# MMCSD2_CTL_CFG register map
Vendor: Texas Instruments
Peripheral module from a debugger description file (folder J7ES).
Registers are 16-bit, read-only, reset 0x0 unless marked. A register's access mark holds for its fields unless they carry their own. Offsets are as the file gives them; lines under a group give offsets from that group; [hi:lo] are bit positions; {n}, {i} and the like mark numbered series; 'fields as' and 'values as' point back to an identical list; <NAME> marks a mode.

## MMCSD2_CTL_CFG (part 1 of 3)
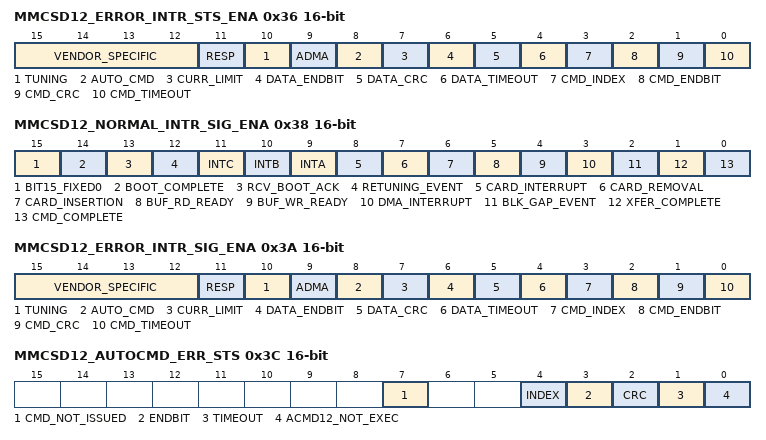
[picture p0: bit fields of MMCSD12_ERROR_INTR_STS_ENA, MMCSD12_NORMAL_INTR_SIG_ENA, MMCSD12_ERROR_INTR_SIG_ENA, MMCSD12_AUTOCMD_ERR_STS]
0x36 MMCSD12_ERROR_INTR_STS_ENA rw — This register is used to enable the register fields.
  [15:12] VENDOR_SPECIFIC — Vendor Specific Error Status Enable N/A
  [11] RESP — Response Error Status Enable (SD Mode Only) 0h: Masked 1h: Enabled
  [10] TUNING — Tuning Error Status Enable (UHS-I Only) 0h: Masked 1h: Enabled
  [9] ADMA — ADMA Error Status Enable 0h: Masked 1h: Enabled
  [8] AUTO_CMD — Auto CMD Error Status Enable (SD Mode Only) 0h: Masked 1h: Enabled
  [7] CURR_LIMIT — Current Limit Error Status Enable 0h: Masked 1h: Enabled
  [6] DATA_ENDBIT — Data End Bit Error Status Enable (SD Mode Only) 0h: Masked 1h: Enabled
  [5] DATA_CRC — Data CRC Error Status Enable (SD Mode Only) 0h: Masked 1h: Enabled
  [4] DATA_TIMEOUT — Data Timeout Error Status Enable (SD Mode Only) 0h: Masked 1h: Enabled
  [3] CMD_INDEX — Command Index Error Status Enable (SD Mode Only) 0h: Masked 1h: Enabled
  [2] CMD_ENDBIT — Command End Bit Error Status Enable (SD Mode Only) 0h: Masked 1h: Enabled
  [1] CMD_CRC — Command CRC Error Status Enable (SD Mode Only) 0h: Masked 1h: Enabled
  [0] CMD_TIMEOUT — Command Timeout Error Status Enable (SD Mode Only) 0h: Masked 1h: Enabled
0x38 MMCSD12_NORMAL_INTR_SIG_ENA access per field — Normal Interrupt Signal Enable Register This register is used to select which interrupt status is indicated to the Host System as the Interrupt. These status bits all share the sample 1 bit interrupt line. Setting any of these bits to 1h enables Interrupt generation.
  [15] BIT15_FIXED0 ro — Fixed to 0 The HD shall control error Interrupts using the
  [14] BOOT_COMPLETE rw — Boot Terminate Interrupt Signal Enable 0h: Masked 1h: Enabled
  [13] RCV_BOOT_ACK rw — Boot Acknowledge Receive Signal Enable 0h: Masked 1h: Enabled
  [12] RETUNING_EVENT rw — Re-Tuning Event Signal Enable (UHS-I Only) 0h: Masked 1h: Enabled
  [11] INTC rw — INT_C Signal Enable (Embedded) 0h: Masked 1h: Enabled
  [10] INTB rw — INT_B Signal Enable (Embedded) 0h: Masked 1h: Enabled
  [9] INTA rw — INT_A Signal Enable (Embedded) 0h: Masked 1h: Enabled
  [8] CARD_INTERRUPT rw — Card Interrupt Signal Enable 0h: Masked 1h: Enabled
  [7] CARD_REMOVAL rw — Card Removal Signal Enable 0h: Masked 1h: Enabled
  [6] CARD_INSERTION rw — Card Insertion Signal Enable 0h: Masked 1h: Enabled
  [5] BUF_RD_READY rw — Buffer Read Ready Signal Enable 0h: Masked 1h: Enabled
  [4] BUF_WR_READY rw — Buffer Write Ready Signal Enable 0h: Masked 1h: Enabled
  [3] DMA_INTERRUPT rw — DMA Interrupt Signal Enable 0h: Masked 1h: Enabled
  [2] BLK_GAP_EVENT rw — Block Gap Event Signal Enable 0h: Masked 1h: Enabled
  [1] XFER_COMPLETE rw — Transfer Complete Signal Enable 0h: Masked 1h: Enabled
  [0] CMD_COMPLETE rw — Command Complete Signal Enable 0h: Masked 1h: Enabled
0x3A MMCSD12_ERROR_INTR_SIG_ENA rw — Error Interrupt Signal Enable Register This register is used to select which interrupt status is notified to the Host System as the Interrupt. These status bits all share the same 1 bit interrupt line. Setting any of these bits to 1h enables Interrupt generation.
  [15:12] VENDOR_SPECIFIC — Vendor Specific Error Signal Enable N/A
  [11] RESP — Response Error Signal Enable (SD Mode Only) 0h: Masked 1h: Enabled
  [10] TUNING — Tuning Error Signal Enable (UHS-I Only) 0h: Masked 1h: Enabled
  [9] ADMA — ADMA Error Signal Enable 0h: Masked 1h: Enabled
  [8] AUTO_CMD — Auto CMD Error Signal Enable (SD Mode Only) 0h: Masked 1h: Enabled
  [7] CURR_LIMIT — Current Limit Error Signal Enable 0h: Masked 1h: Enabled
  [6] DATA_ENDBIT — Data End Bit Error Signal Enable (SD Mode Only) 0h: Masked 1h: Enabled
  [5] DATA_CRC — Data CRC Error Signal Enable (SD Mode Only) 0h: Masked 1h: Enabled
  [4] DATA_TIMEOUT — Data Timeout Error Signal Enable (SD Mode Only) 0h: Masked 1h: Enabled
  [3] CMD_INDEX — Command Index Error Signal Enable (SD Mode Only) 0h: Masked 1h: Enabled
  [2] CMD_ENDBIT — Command End Bit Error Signal Enable (SD Mode Only) 0h: Masked 1h: Enabled
  [1] CMD_CRC — Command CRC Error Signal Enable (SD Mode Only) 0h: Masked 1h: Enabled
  [0] CMD_TIMEOUT — Command Timeout Error Signal Enable (SD Mode Only) 0h: Masked 1h: Enabled
0x3C MMCSD12_AUTOCMD_ERR_STS — This register is used to indicate CMD12 response error of Auto CMD12 and CMD23 response error of Auto CMD23. The Host driver can determine what kind of Auto CMD12/CMD23 errors occur by this register. Auto CMD23 errors are indicated in bit 04-01. This register is valid only when the Auto CMD Error is set.
  [7] CMD_NOT_ISSUED — Command Not Issued By Auto CMD12 Error Setting this bit to 1h means CMD_wo_DAT is not executed due to an Auto CMD12 error (D04- D01) in this register. This bit is set to 0h when Auto CMD Error is generated by Auto CMD23. 0h: No Error 1h: Not Issued
  [4] INDEX — Auto CMD Index Error Occurs if the Command Index error occurs in response to a command. 0h: No Error 1h: Error
  [3] ENDBIT — Auto CMD End Bit Error Occurs when detecting that the end bit of command response is 0h. 0h: No Error 1h: End Bit Error Generated
  [2] CRC — Auto CMD CRC Error Occurs when detecting a CRC error in the command response. 0h: No Error 1h: CRC Error Generated
  [1] TIMEOUT — Auto CMD Timeout Error Occurs if the no response is returned within 64 SDCLK cycles from the end bit of the command. If this bit is set to 1h, the other error status bits (D04 - D02) are meaningless. 0h: No Error 1h: Timeout
  [0] ACMD12_NOT_EXEC — Auto CMD12 not Executed If memory multiple block data transfer is not started due to command error, this bit is not set because it is not necessary to issue Auto CMD12. Setting this bit to 1h means the HC cannot issue Auto CMD12 to stop memory multiple block transfer due to some error. If this bit is set to 1h, other error status bits (D04 - D01) are meaningless. This bit is set to 0h when Auto CMD Error is generated by Auto CMD23. 0h: Executed 1h: Not Executed
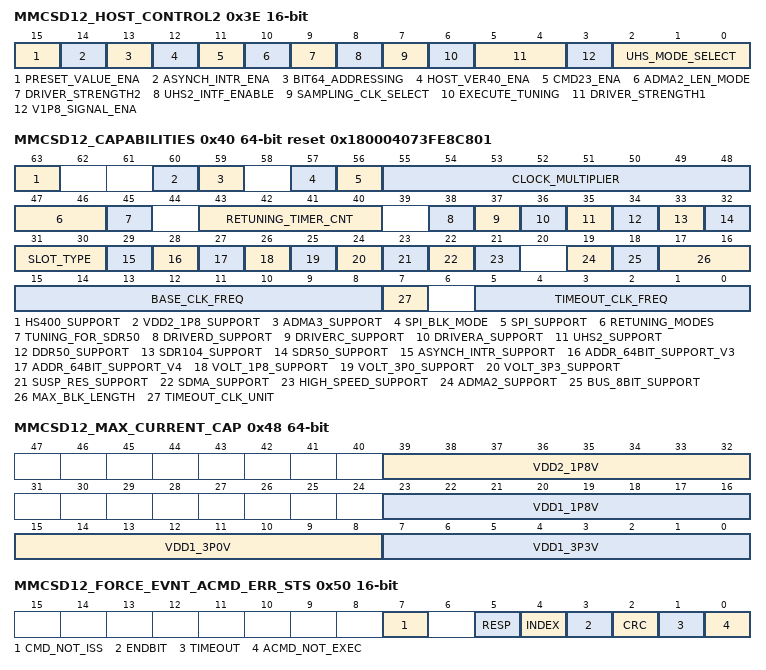
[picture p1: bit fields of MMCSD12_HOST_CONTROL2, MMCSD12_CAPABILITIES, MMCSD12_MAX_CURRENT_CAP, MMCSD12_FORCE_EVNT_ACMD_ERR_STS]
0x3E MMCSD12_HOST_CONTROL2 rw — This register is used to program UHS Mode Select, Driver Strength Select, Execute Tuning, Sampling Clock Select, Asynchronous Interrupt Enable and Preset Value Enable.
  [15] PRESET_VALUE_ENA — Preset Value Enable Host Controller Version 3.00 supports this bit. As the operating SDCLK frequency and I/O driver strength depend on the Host System implementation, it is difficult to determine these parameters in the Standard Host Driver. When the If this bit is set to 0h, SDCLK Frequency Select, Clock Generator Select in the If this bit is set to 1h, SDCLK Frequency Select, Clock Generator Select in the 0h: SDCLK and Driver Strength are controlled by Host Driver 1h: Automatic Selection by Preset Value are Enabled
  [14] ASYNCH_INTR_ENA — Asynchronous Interrupt Enable This bit can be set to 1h if a card support asynchronous interrupt and the 0h: Disabled 1h: Enabled
  [13] BIT64_ADDRESSING — 64-bit Addressing This field is effective when the Host Controller selects either of 32-bit or 64-bit addressing modes to access system memory. Whether 32-bit or 64-bit is determined by OS installed in a host system. Host Driver sets this bit depends on addressing mode of installed OS. Refer to 64-bit System Address Support in the 0h: 32-bits Addressing 1h: 64-bits Addressing
  [12] HOST_VER40_ENA — Host Version 4 Enable This bit selects either Version 3.00 compatible mode or Version 4.00 mode. In Version 4.00, support of 64-bit System Addressing is modified. All DMAs support 64-bit System Addressing. UHS-II supported Host Driver shall enable this bit. In Version 4.10, supported 32-bit Block Count for all operations. Functions of following fields are modified. SDMA uses the ADMA3 is selected by 128-bit descriptor is used instead of 96-bit descriptor when 64-bit Addressing is set to 1h. Either 32-bit or 64-bit system addressing is selected by 64-bit Addressing bit in this register instead of SDMA System Address register ( 0h: Version 3.00 Compatible Mode 1h: Version 4.Mode
  [11] CMD23_ENA — CMD23 Enable In memory card initialization, Host Driver Version 4.10 checks whether card supports CMD23 by checking a bit SCR[33]. If the card supports CMD23 (SCR[33] = 1h), this bit is set to 1h. This bit is used to select Auto CMD23 or Auto CMD12 for ADMA3 datatransfer. Refer to
  [10] ADMA2_LEN_MODE — ADMA2 Length Mode This bit selects one of ADMA2 Length Modes either 16-bit or 26-bit. 0h: 16-bit Data Length Mode 1h: 26-bit Data Length Mode
  [9] DRIVER_STRENGTH2 — Driver Strength Select This is the programmed Drive Strength output and Bit[2] of the sdhccore_drivestrength value.
  [8] UHS2_INTF_ENABLE — UHS-II Interface Enable This bit is used to enable UHS-II Interface. Before trying to start UHS-II initialization, this bit shall be set to 1h. Before trying to start SD mode initialization, this bit shall be set to 0h. This bit is used to enable UHS-II IF Detection, Lane Synchronization and In Dormant State in the Host Controller shall not leave unused SD 4-bit Interface lines (CLK, CMD and DAT[3:2]) floating in UHS-II mode by using pull-up or driving to low. When DAT[2] is used as interrupt input in UHS-II mode, DAT[2] of Host Controller is set to input and then DAT[2] of SDIO card is set to output to avoid conflict. 0h: 4-bit SD Interface Enabled 1h: UHS-II Interface Enabled
  [7] SAMPLING_CLK_SELECT — Sampling Clock Select (UHS-I Only) This bit is set by tuning procedure when the 0h: Fixed clock is used to sample data 1h: Tuned clock is used to sample data
  [6] EXECUTE_TUNING — Execute Tuning (UHS-I Only) This bit is set to 1h to start tuning procedure and automatically cleared when tuning procedure is completed. The result of tuning is indicated to the 0h: Not Tuned or Tuning Completed 1h: Execute Tuning
  [5:4] DRIVER_STRENGTH1 — Driver Strength Select (UHS-I Only) Host Controller output driver in 1.8 V signaling is selected by this bit. In 3.3 V signaling, this field is not effective. This field can be set depends on Driver Type A, C and D support bits in the If If 0h: Driver Type B is Selected (Default) 1h: Driver Type A is Selected 2h: Driver Type C is Selected 3h: Driver Type D is Selected
  [3] V1P8_SIGNAL_ENA — 1.8 V Signaling Enable (UHS-I Only) This bit controls voltage regulator for I/O cell. 3.3 V is supplied to the card regardless of signaling voltage. Setting this bit from 0h to 1h starts changing signal voltage from 3.3 V to 1.8 V. 1.8 V regulator output shall be stable within 5 ms. Host Controller clears this bit if switching to 1.8 V signaling fails. Clearing this bit from 1h to 0h starts changing signal voltage from 1.8 V to 3.3 V. 3.3 V regulator output shall be stable within 5 ms. Host Driver can set this bit to 1h when Host Controller supports 1.8 V signaling (one of support bits is set to 1h: SDR50, SDR104 or DDR50 in the 0h: 3.3 V Signaling 1h: 1.8 V Signaling
  [2:0] UHS_MODE_SELECT — UHS Mode Select (UHS-I Only) This field is used to select one of UHS-I modes or UHS-II mode. In case of UHS-I mode, this field is effective when the If the 0h: SDR12 1h: SDR25 2h: SDR50 3h: SDR104 4h: DDR50 5h: HS400 6h: Reserved 7h: UHS-II When SDR50, SDR104 or DDR50 is selected for SDIO card, interrupt detection at the block gap shall not be used. Read Wait timing is changed for these modes. Refer to the SDIO Specification Version 3.00 for more details.
0x40 MMCSD12_CAPABILITIES 64-bit reset 0x180004073FE8C801 — This register provides the HD with information specific to the HC implementation. The HC may implement these values as fixed or loaded from flash memory during power on initialization.
  [63] HS400_SUPPORT — HS400 Support 0h: HS400 is Not Supported 1h: HS400 is Supported
  [60] VDD2_1P8_SUPPORT — 1.8 V VDD2 Support This bit indicates that support of VDD2 on Host system. 0h: 1.8 V VDD2 is not supported 1h: 1.8 V VDD2 is supported
  [59] ADMA3_SUPPORT — ADMA3 Support This bit indicates that support of ADMA3 on Host Controller. 0h: ADMA3 is not supported 1h: ADMA3 is supported
  [57] SPI_BLK_MODE — SPI Block Mode This bit indicates whether SPI Block Mode is supported or not. 0h: Not Supported 1h: Supported
  [56] SPI_SUPPORT — SPI Mode This bit indicates whether SPI Mode is supported or not. 0h: Not Supported 1h: Supported
  [55:48] CLOCK_MULTIPLIER — Clock Multiplier This field indicates clock multiplier value of programmable clock generator. Refer to the FFh: Clock Multiplier M = 256 ---- 02h: Clock Multiplier M = 3 01h: Clock Multiplier M = 2 00h: Clock Multiplier is Not Supported
  [47:46] RETUNING_MODES — Re-tuning Modes (UHS-I Only) This field defines the re-tuning capability of a Host Controller and how to manage the data transfer length and a Re-Tuning Timer by the Host Driver. 0h: Mode 1 1h: Mode 2 2h: Mode 3 3h: Reserved There are two re-tuning timings: Re-Tuning Request and expiration of a Re-Tuning Timer. By receiving either timing, the Host Driver executes the re-tuning procedure just before a next command issue.
  [45] TUNING_FOR_SDR50 — Use Tuning for SDR50 (UHS-I Only) If this bit is set to 1h, this Host Controller requires tuning to operate SDR50 (tuning is always required to operate SDR104). 0h: SDR50 does not require tuning 1h: SDR50 requires tuning
  [43:40] RETUNING_TIMER_CNT — Timer Count for Re-Tuning (UHS-I Only) This field indicates an initial value of the Re-Tuning Timer for Re-Tuning Mode 1 to 3. 0h - Get information via other source 1h = 1 seconds 2h = 2 seconds 3h = 4 seconds 4h = 8 seconds ---- n = 2 ---- Bh = 1024 seconds Fh - Ch = Reserved
  [38] DRIVERD_SUPPORT — Driver Type D Support (UHS-I Only) This bit indicates support of Driver Type D for 1.8 Signaling. 0h: Driver Type D is Not Supported 1h: Driver Type D is Supported
  [37] DRIVERC_SUPPORT — Driver Type C Support (UHS-I Only) This bit indicates support of Driver Type C for 1.8 Signaling. 0h: Driver Type C is Not Supported 1h: Driver Type C is Supported
  [36] DRIVERA_SUPPORT — Driver Type A Support (UHS-I Only) This bit indicates support of Driver Type A for 1.8 Signaling. 0h: Driver Type A is Not Supported 1h: Driver Type A is Supported
  [35] UHS2_SUPPORT — UHS-II Support (UHS-II Only) This bit indicates whether Host Controller supports UHS-II. If this bit is set to 1h, the 0h: UHS-II is Not Supported 1h: UHS-II is Supported
  [34] DDR50_SUPPORT — DDR50 Support (UHS-I Only) This bit indicates whether DDR50 is supported or not. 0h: DDR50 is Not Supported 1h: DDR50 is Supported
  [33] SDR104_SUPPORT — SDR104 Support (UHS-I Only) This bit indicates whether SDR104 is supported or not. SDR104 requires tuning. 0h: SDR104 is Not Supported 1h: SDR104 is Supported
  [32] SDR50_SUPPORT — SDR50 Support (UHS-I Only) If SDR104 is supported, this bit shall be set to 1h. Bit 40 indicates whether SDR50 requires tuning or not. 0h: SDR50 is Not Supported 1h: SDR50 is Supported
  [31:30] SLOT_TYPE — Slot Type This field indicates usage of a slot by a specific Host System (a host controller register set is defined per slot). Embedded slot for one device (1h) means that only one non-removable device is connected to a SD bus slot. Shared Bus Slot (2h) can be set if Host Controller supports Shared Bus Control register. The Standard Host Driver controls only a removable card or one embedded device is connected to a SD bus slot. If a slot is configured for shared bus (2h), the Standard Host Driver does not control embedded devices connected to a shared bus. Shared bus slot is controlled by a specific host driver developed by a Host System. 0h: Removable Card Slot 1h: Embedded Slot for One Device 2h: Shared Bus Slot (SD Mode) 3h: UHS-II Multiple Embedded Devices
  [29] ASYNCH_INTR_SUPPORT — Asynchronous Interrupt Support (SD Mode Only) Refer to SDIO Specification Version 3.00 about asynchronous interrupt. 0h: Asynchronous Interrupt Not Supported 1h: Asynchronous Interrupt Supported
  [28] ADDR_64BIT_SUPPORT_V3 — 64-bit System Address Support for V3 Meaning of this bit is different depends on Versions. Host Controller Version 3.00 and Version 4.10 use this bit as 64-bit System Address support for V3 mode. Host Controller Version 4.00 uses this bit as 64-bit System Address support for both V3 and V4 modes. SDMA cannot be used in 64-bit Addressing in Version 3 mode. If this bit is set to 1h, 64-bit ADMA2 with using 96-bit Descriptor may be enabled as follows: In case of Host Controller Version 3, 64-bit ADMA2 is enabled by 0h: 64-bit System Address for V3 is not Supported 1h: 64-bit System Address for V3 is Supported
  [27] ADDR_64BIT_SUPPORT_V4 — 64-bit System Address Support for V4 This bit is added from Version 4.10. Setting 1h to this bit indicates that the Host Controller supports 64-bit System Addressing of Version 4 mode. When this bit is set to 1h, full or a part of 64-bit address should be used to decode Host Controller Registers so that Host Controller Registers can be placed above system memory area. 64-bit address decode of Host Controller Registers is effective regardless of setting to the If this bit is set to 1h, 64-bit DMA Addressing for Version 4 is enabled by setting 0h: 64-bit System Address for V4 is not Supported 1h: 64-bit System Address for V4 is Supported
  [26] VOLT_1P8_SUPPORT — Voltage Support 1.8 V This bit indicates whether the HC supports 1.8 V. 0h: 1.8 V Not Supported 1h: 1.8 V Supported
  [25] VOLT_3P0_SUPPORT — Voltage Support 3.0 V This bit indicates whether the HC supports 3.0 V. 0h: 3.0 V Not Supported 1h: 3.0 V Supported
  [24] VOLT_3P3_SUPPORT — Voltage Support 3.3 V This bit indicates whether the HC supports 3.3 V. 0h: 3.3 V Not Supported 1h: 3.3 V Supported
  [23] SUSP_RES_SUPPORT — Suspend/Resume Support This bit indicates whether the HC supports Suspend/Resume functionality. If this bit is 0h, the Suspend and Resume mechanism are not supported and the HD shall not issue either Suspend/Resume commands. 0h: Not Supported 1h: Supported
  [22] SDMA_SUPPORT — SDMA Support This bit indicates whether the HC is capable of using DMA to transfer data between system memory and the HC directly. Version 4.10 Host Controller shall support SDMA if ADMA2 is supported. 0h: SDMA Not Supported 1h: SDMA Supported
  [21] HIGH_SPEED_SUPPORT — High Speed Support This bit indicates whether the HC and the Host System support High Speed mode and they can supply SD Clock frequency from 25 MHz to 50 MHz (for SD)/20 MHz to 52 MHz (for MMC). 0h: High Speed Not Supported 1h: High Speed Supported
  [19] ADMA2_SUPPORT — ADMA2 Support 0h: ADMA2 Not support 1h: ADMA2 support
  [18] BUS_8BIT_SUPPORT — 8-bit Support for Embedded Device (Embedded) This bit indicates whether the Host Controller is capable of using 8-bit bus width mode. This bit is not effective when the 0h: 8-bit Bus Width Not Supported 1h: 8-bit Bus Width Supported
  [17:16] MAX_BLK_LENGTH — Max Block Length This value indicates the maximum block size that the HD can read and write to the buffer in the HC. The buffer shall transfer this block size without wait cycles. Three sizes can be defined as indicated below. 0h: 512 byte 1h: 1024 byte 2h: 2048 byte 3h: 4096 byte
  [15:8] BASE_CLK_FREQ — Base Clock Frequency for SD Clock (1) 6-bit Base Clock Frequency: This mode is supported by the Host Controller Version 1.00 and 2.00. Upper 2-bit is not effective and always 0. Unit values are 1 MHz. The supported clock range is 10 MHz to 63 MHz. 11xx xxxxb: Not Supported 0011 1111b: 63 MHz 0000 0010b: 2 MHz 0000 0001b: 1 MHz 0000 0000b: Get Information via another method (2) 8-bit Base Clock Frequency: This mode is supported by the Host Controller Version 3.00. Unit values are 1 MHz. The supported clock range is 10 MHz to 255 MHz. FFh: 255 MHz 02h: 2 MHz 01h: 1 MHz 00h: Get Information via another method If the real frequency is 16.5 MHz, the lager value shall be set 0001 0001b (17 MHz) because the Host Driver use this value to calculate the clock divider value (refer to the
  [7] TIMEOUT_CLK_UNIT — Timeout Clock Unit This bit shows the unit of base clock frequency used to detect Data Timeout Error ( 0h: KHz 1h: MHz
  [5:0] TIMEOUT_CLK_FREQ — Timeout Clock Frequency This bit shows the base clock frequency used to detect Data Timeout Error ( 0h: Get Information via another method Not 0h: 1 KHz to 63 KHz/1 MHz to 63 MHz
0x48 MMCSD12_MAX_CURRENT_CAP 64-bit — This register indicates maximum current capability for each voltage.
  [39:32] VDD2_1P8V — Maximum Current for 1.8 V VDD2
  [23:16] VDD1_1P8V — Maximum Current for 1.8 V VDD1
  [15:8] VDD1_3P0V — Maximum Current for 3.0 V VDD1
  [7:0] VDD1_3P3V — Maximum Current for 3.3 V VDD1
0x50 MMCSD12_FORCE_EVNT_ACMD_ERR_STS access per field — This register is not physically implemented, rather it is an address where the register can be written. Writing 1h: set each bit of the register Writing 0h: no effect By setting a bit in this register, the correspondent bit is set in the
  [7] CMD_NOT_ISS wo — Force Event for Command Not Issued by AUTO CMD12 Error 0h: Not Affected 1h: Command Not Issued By Auto CMD12 Error Status is set
  [5] RESP wo — Force Event for AUTO CMD Response Error 0h: Not Affected 1h: Auto CMD Response Error Status is set
  [4] INDEX wo — Force Event for AUTO CMD Index Error 0h: Not Affected 1h: Auto CMD Index Error Status is set
  [3] ENDBIT wo — Force Event for AUTO CMD End Bit Error 0h: Not Affected 1h: Auto CMD End bit Error Status is set
  [2] CRC wo — Force Event for AUTO CMD Timeout Error 0h: Not Affected 1h: Auto CMD CRC Error Status is set
  [1] TIMEOUT wo — Force Event for AUTO CMD Timeout Error 0h: Not Affected 1h: Auto CMD Timeout Error Status is set
  [0] ACMD_NOT_EXEC wo — Force Event for AUTO CMD12 Not Executed 0h: Not Affected 1h: Auto CMD12 Not Executed Status is set
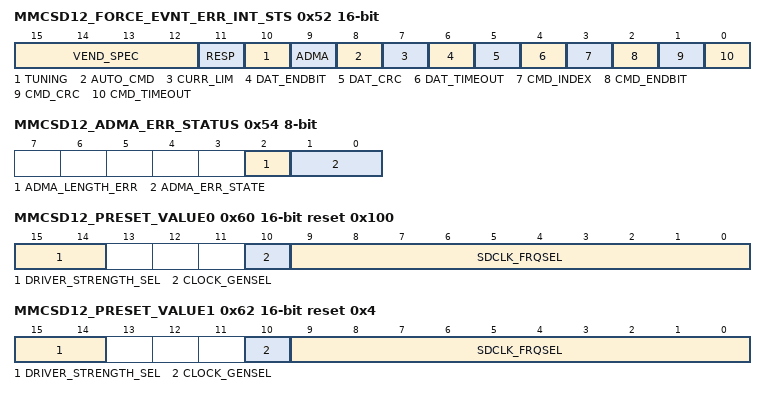
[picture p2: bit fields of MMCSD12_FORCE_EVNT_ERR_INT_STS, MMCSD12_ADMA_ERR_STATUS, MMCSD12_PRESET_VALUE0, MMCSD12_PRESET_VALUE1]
0x52 MMCSD12_FORCE_EVNT_ERR_INT_STS wo — This register is not physically implemented, rather it is an address where the register can be written. The register is not a physically implemented register. Rather, it is an address at which the register can be written. The effect of a write to this address will be reflected in the register if the corresponding bit of the register is set. Writing 1h: set each bit of the register Writing 0h: no effect
  [15:12] VEND_SPEC
  [11] RESP — Force Event for Response Error 0h: Not Affected 1h: Response Error Status is set
  [10] TUNING — Force Event for Tuning Error 0h: Not Affected 1h: Tuning Error Status is set
  [9] ADMA — Force Event for ADMA Error 0h: Not Affected 1h: ADMA Error Status is set
  [8] AUTO_CMD — Force Event for Auto CMD Error 0h: Not Affected 1h: Auto CMD Error Status is set
  [7] CURR_LIM — Force Event for Current Limit Error 0h: Not Affected 1h: Current Limit Error Status is set
  [6] DAT_ENDBIT — Force Event for Data End Bit Error 0h: Not Affected 1h: Data End Bit Error Status is set
  [5] DAT_CRC — Force Event for Data CRC Error 0h: Not Affected 1h: CRC Error Status is set
  [4] DAT_TIMEOUT — Force Event for Data Timeout Error 0h: Not Affected 1h: Timeout Error Status is set
  [3] CMD_INDEX — Force Event for Command Index Error 0h: Not Affected 1h: Command Index Error Status is set
  [2] CMD_ENDBIT — Force Event for Command End Bit Error 0h: Not Affected 1h: Command End Bit Error Status is set
  [1] CMD_CRC — Force Event for Command CRC Error 0h: Not Affected 1h: Command CRC Error Status is set
  [0] CMD_TIMEOUT — Force Event for CMD Timeout Error 0h: Not Affected 1h: Command Timeout Error Status is set
0x54 MMCSD12_ADMA_ERR_STATUS 8-bit — When the ADMA Error interrupt occur, this register holds the ADMA State ([1-0] ADMA_ERR_STATE) and the register holds address around the error descriptor.
  [2] ADMA_LENGTH_ERR — ADMA Length Mismatch Error This error occurs in the following 2 cases. While the 0h: No Error 1h: Error
  [1:0] ADMA_ERR_STATE — ADMA Error State This field indicates the state of ADMA when error is occurred during ADMA data transfer. This field never indicates '2h' because ADMA never stops in this state. D01 - D00: ADMA Error State when error occurred Contents of SYS_SDR register 0h: ST_STOP (Stop DMA) Points to next of the error descriptor 1h: ST_FDS (Fetch Descriptor) Points to the error descriptor 2h: Never set this state (Not used) 3h: ST_TFR (Transfer Data) Points to the next of the error descriptor
0x58 MMCSD12_ADMA_SYS_ADDRESS 64-bit rw reset not defined — This register contains the physical address used for ADMA data transfer.
  [63:0] ADMA_ADDR — ADMA System Address The 32-bit addressing Host Driver uses lower 32-bit of this register (upper 32-bit should be set to 0h) and shall program Descriptor Table on 32-bit boundary and set 32-bit boundary address to this register. DMA2/3 ignores lower 2-bit of this register and assumes it to be 0h. DMA in 64-bit addressing. The 64-bit addressing Host Driver uses all bits of this register and shall program Descriptor Table on 64-bit boundary and set 64-bit boundary address to this register. DMA2/3 ignores lower 3-bit of this register andassumes it to be 0h. If the This register holds byte address of executing command of the Descriptor table. At the start of ADMA2, the Host Driver shall set start address of the Descriptor table. The ADMA increments this register address, which points to next line, when every fetching a Descriptor line. When the ADMA Error Interrupt is generated, this register shall hold the Descriptor address depending on the ADMA state. This register is set by ADMA3. Host Driver is not necessary to set this register. The ADMA3 increments address of this register, which points to next line, when every time fetching a Descriptor line. When Error Interrupt is generated, this register shall hold the Descriptor address depending on the ADMA state. Register Value - Addressing Mode - 32-bit System Address Register Value - xxxxxxxx_xxxxxxxxh Addressing Mode - 64-bit System Address
0x60 MMCSD12_PRESET_VALUE0 reset 0x100 — This register is used to read the SDCLK Frequency Select Value, Clock Generator Select Value, Driver Strength Select Value. When the [15] PRESET_VALUE_ENA bit is set to 1h, SDCLK/RCLK Frequency Select and Clock Generator Select in the register, and Driver Strength Select in the register are automatically set based on the Selected Bus Speed Mode (see ). This means the Host Driver needs not set these fields when preset is enabled. Before starting the initialization sequence, the Host Driver needs to set a clock preset value to SDCLK/RCLK Frequency Select in the register. The [15] PRESET_VALUE_ENA bit can be set after initialization completed. shows the conditions to select one of preset value registers.
  [15:14] DRIVER_STRENGTH_SEL — Driver Strength Select Value (UHS-I Only) Driver Strength is supported by 1.8 V signaling bus speed modes. This field is meaningless for 3.3 V signaling. 0h: Driver Type D is Selected 1h: Driver Type C is Selected 2h: Driver Type A is Selected 3h: Driver Type B is Selected
  [10] CLOCK_GENSEL — Clock Generator Select Value This bit is effective when Host Controller supports programmable clock generator. 0h: Host Controller Version 2.00 Compatible Clock Generator 1h: Programmable Clock Generator
  [9:0] SDCLK_FRQSEL — SDCLK Frequency Select Value 10-bit preset value to set the
0x62 MMCSD12_PRESET_VALUE1 reset 0x4 — This register is used to read the SDCLK Frequency Select Value, Clock Generator Select Value, Driver Strength Select Value.
  fields as MMCSD12_PRESET_VALUE0
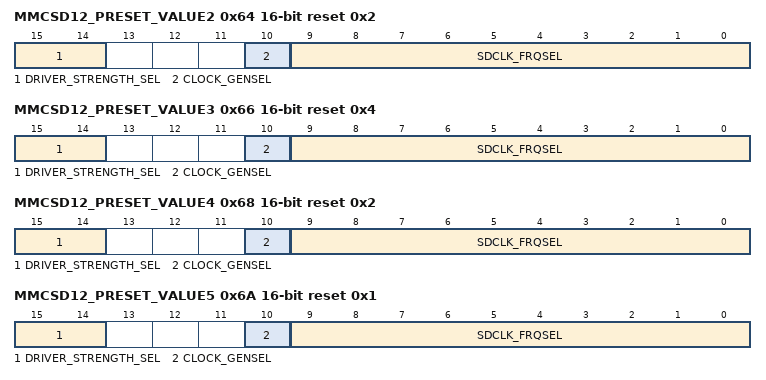
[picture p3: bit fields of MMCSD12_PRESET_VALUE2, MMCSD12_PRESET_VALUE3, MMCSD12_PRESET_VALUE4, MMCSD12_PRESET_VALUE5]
0x64 MMCSD12_PRESET_VALUE2 reset 0x2 — This register is used to read the SDCLK Frequency Select Value, Clock Generator Select Value, Driver Strength Select Value.
  fields as MMCSD12_PRESET_VALUE0
0x66 MMCSD12_PRESET_VALUE3 reset 0x4 — This register is used to read the SDCLK Frequency Select Value, Clock Generator Select Value, Driver Strength Select Value.
  fields as MMCSD12_PRESET_VALUE0
0x68 MMCSD12_PRESET_VALUE4 reset 0x2 — This register is used to read the SDCLK Frequency Select Value, Clock Generator Select Value, Driver Strength Select Value.
  fields as MMCSD12_PRESET_VALUE0
0x6A MMCSD12_PRESET_VALUE5 reset 0x1 — This register is used to read the SDCLK Frequency Select Value, Clock Generator Select Value, Driver Strength Select Value.
  fields as MMCSD12_PRESET_VALUE0
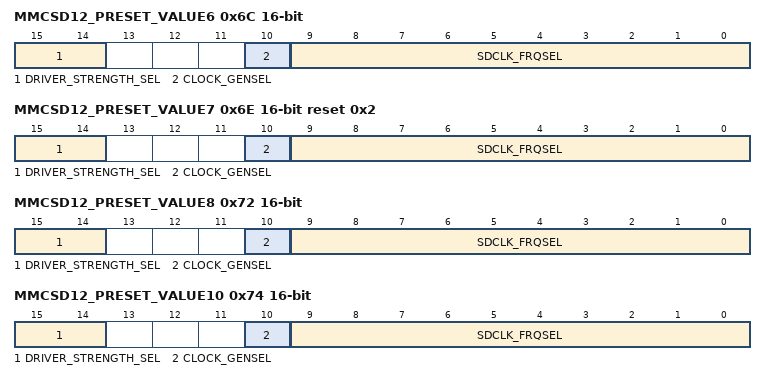
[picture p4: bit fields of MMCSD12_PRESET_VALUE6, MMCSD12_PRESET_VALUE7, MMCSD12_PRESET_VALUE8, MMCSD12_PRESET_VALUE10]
0x6C MMCSD12_PRESET_VALUE6 — This register is used to read the SDCLK Frequency Select Value, Clock Generator Select Value, Driver Strength Select Value.
  fields as MMCSD12_PRESET_VALUE0
0x6E MMCSD12_PRESET_VALUE7 reset 0x2 — This register is used to read the SDCLK Frequency Select Value, Clock Generator Select Value, Driver Strength Select Value.
  fields as MMCSD12_PRESET_VALUE0
0x72 MMCSD12_PRESET_VALUE8 — This register is used to read the SDCLK Frequency Select Value, Clock Generator Select Value, Driver Strength Select Value.
  fields as MMCSD12_PRESET_VALUE0
0x74 MMCSD12_PRESET_VALUE10 — This register is used to read the SDCLK Frequency Select Value, Clock Generator Select Value, Driver Strength Select Value.
  fields as MMCSD12_PRESET_VALUE0
0x78 MMCSD12_ADMA3_DESC_ADDRESS 64-bit rw reset not defined — The start address of Integrated DMA Descriptor is set to this register.
  [63:0] INTG_DESC_ADDR — ADMA3 Integrated Descriptor Address The start address of Integrated DMA Descriptor is set to this register. Writing to a specific address starts ADMA3 depends on 32-bit/64-bit address-ing. The ADMA3 fetches one Descriptor Address and increments this field to indicate the next Descriptor address. The 32-bit addressing Host Driver uses lower 32-bit of this register and shall program Descriptor Table on 32-bit boundary. ADMA3 ignores lower 2-bit of this register and assumes it to be 0h. Writing to 07Bh starts ADMA3 data transfer. The 64-bit addressing Host Driver uses all 64-bit of this register and shall program Descriptor Table on 64-bit boundary. ADMA3 ignores lower 3-bit of this register and assumes it to be 0h. Writing to 07Fh starts ADMA3 data transfer. Register Value - Register Value - xxxxxxxx_xxxxxxxxh Addressing Mode - 64-bit System Address
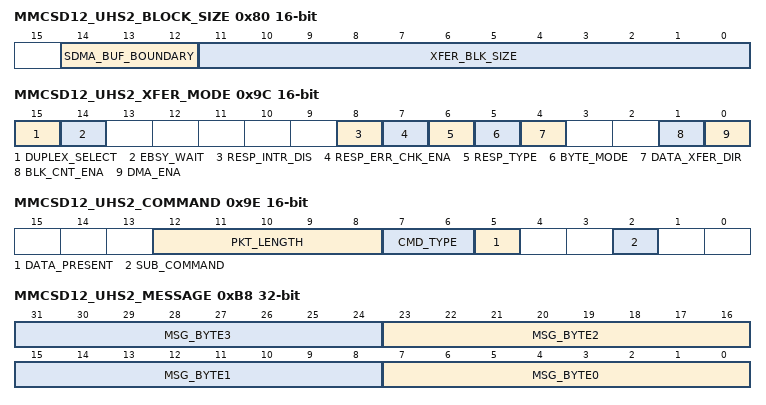
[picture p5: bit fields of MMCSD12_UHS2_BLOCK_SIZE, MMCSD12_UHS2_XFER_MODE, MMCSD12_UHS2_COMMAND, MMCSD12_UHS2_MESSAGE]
0x80 MMCSD12_UHS2_BLOCK_SIZE access per field — This register is used to configure the number of bytes in a data block.
  [14:12] SDMA_BUF_BOUNDARY rw — UHS-II SDMA Buffer Boundary (SDMA only) When system memory is managed by paging, SDMA data transfer is performed in unit of paging. A page size of system memory management is set to this field. Host Controller generates the DMA Interrupt at the page boundary and requests the Host Driver to update the At the end of transfer, the Host Controller may issue or may not issue DMA Interrupt. In particular, DMA Interrupt shall not be issued after Transfer Complete Interrupt is issued (see These bits shall be supported when the 0h: 4K bytes (Detects A11 carry out) 1h: 8K bytes (Detects A12 carry out) 2h: 16K Bytes (Detects A13 carry out) 3h: 32K Bytes (Detects A14 carry out) 4h: 64K bytes (Detects A15 carry out) 5h: 128K Bytes (Detects A16 carry out) 6h: 256K Bytes (Detects A17 carry out) 7h: 512K Bytes (Detects A18 carry out)
  [11:0] XFER_BLK_SIZE rw — UHS-II Block Size This bit field specifies the block size of data packet. SD Memory Card uses a fixed block size of 512 bytes. Variable block size may be used for SDIO. The maximum value is 2048 Bytes because CRC16 covers up to 2048 bytes. This bit field is effective when the 0000h - No data transfer 0001h - 1 Byte 0002h - 2 Bytes 0003h - 3 Bytes ... ... 01FFh - 511 Bytes 0200h - 512 Bytes ... ... 0800h - 2048 Bytes
0x84 MMCSD12_UHS2_BLOCK_COUNT 32-bit rw — This register is used to configure the number of data blocks.
  [31:0] XFER_BLK_COUNT — UHS-II Block Count This register is effective when the This register should be accessed only when no transaction is executing (after transactions are stopped). During data transfer, read operations on this register may return an invalid value and write operations are ignored. 00000000h: Stop Count 00000001h: 1 block 00000002h: 2 blocks ... ... FFFFFFFFh: 4G blocks - 1
{0x88+4i} MMCSD12_UHS2_COMMAND_PKT_{i} 8-bit rw (i=0..18) — UHS-II Command Packet image is set to this register. The maximum length is 20 bytes (see ). The command length varies depends on a Command Packet type. The length is specified by the register.
  [7:0] CMD_PKT_BYTE — Command Packet Byte UHS-II Command Packet image is set to this register. The command length varies depends on a Command Packet type.
0x9C MMCSD12_UHS2_XFER_MODE access per field — This register is used to control the operations of data transfers. On issuing a Command Packet, a Command Packet image is set to UHS-II Command Packet register (see - ) but Host Controller does not analyze the setting of UHS-II Command Packet register. Instead, Host Controller refers setting of this register to issue a Command Packet to make the control easy. Setting of these registers shall be correspondent.
  [15] DUPLEX_SELECT rw — Half/Full Select Use of 2 lane half duplex mode is determined by Host Driver. 0h: Full Duplex Mode 1h: 2 Lane Half Duplex Mode
  [14] EBSY_WAIT rw — EBSY Wait This bit is set when issuing a command which is accompanied by EBSY packet to indicate end of command execution. Busy is expected for CCMD with R1b/R5b type and DCMD with data transfer. If this bit is set to 1h, Host Controller waits receiving of EBSY packet and on receiving EBSY packet, the Setting of the 0h: Issue a command without busy 1h: Wait EBSY
  [8] RESP_INTR_DIS rw — Response Interrupt Disable Host Controller Version 4.00 supports response error check function to avoid overhead of response error check by Host Driver. Only R1 or R5 can be checked. If Host Driver checks response error, sets this bit to 0h and waits the 0h: Response Interrupt is enabled 1h: Response Interrupt is disabled
  [7] RESP_ERR_CHK_ENA rw — Response Error Check Enable Host Controller Version 4.00 supports response error check function to avoid overhead of response error check by Host Driver. Only R1 or R5 can be checked. If Host Driver checks response error, this bit is set to 0h and the 0h: Response Error Check is disabled 1h: Response Error Check is enabled
  [6] RESP_TYPE rw — Response Type R1/R5 When response error check is enabled, this bit selects either R1 or R5 response types. Two types of response checks are supported: R1 for memory and R5 for SDIO. Error Statuses Checked in R1: Response Flags Checked in R5: 0h: R1 (Memory) 1h: R5 (SDIO)
  [5] BYTE_MODE rw — Block/Byte Mode This bit specifies whether data transfer is in byte mode or block mode when the 0h: Block Mode 1h: Byte Mode
  [4] DATA_XFER_DIR rw — Data Transfer Direction This bit specifies direction of data transfer when the 0h: Read (Card to Host) 1h: Write (Host to Card)
  [1] BLK_CNT_ENA rw — Block Count Enable This bit specifies whether data transfer uses the 0h: Block Count Disabled 1h: Block Count Enabled
  [0] DMA_ENA rw — DMA Enable This bit selects whether DMA is used or not and is effective to a command with data transfer. One of DMA types is selected by the 0h: DMA is disabled 1h: DMA is enabled
0x9E MMCSD12_UHS2_COMMAND access per field — This register is used to program the Command for host controller.
  [12:8] PKT_LENGTH rw — UHS-II Command Packet Length A command packet length, which is set in the UHS-II Command Packet register ( 00011b – 00000b: 3-0 Bytes (Not used) 00100b: 4 Bytes .... .... 10100b: 20 Bytes 11111b – 10101b
  [7:6] CMD_TYPE rw — Command Type This field is used to distinguish a specific command like abort command. If this field is set to 0h, the UHS-II RES Packet is stored in UHS-II Response register ( 0h: Normal Command 1h: TRANS_ABORT CCMD 2h: CMD12 or SDIO Abort command 3h: Go Dormant Command
  [5] DATA_PRESENT rw — Data Present This bit specifies whether the command is accompanied by data packet. 0h: No Data Present 1h: Data Present
  [2] SUB_COMMAND rw — Sub Command Flag This bit is added from Version 4.10 to distinguish a main command or sub command. When issuing a main command, this bit is set to 0h and when issuing a sub command, this bit is set to 1h. Setting of this bit is checked by the 0h: Sub Command 1h: Main Command
{0xA0+4i} MMCSD12_UHS2_RESPONSE_{i} 8-bit (i=0..18) — This register is used to store received UHS-II RES Packet image. Host Controller saves received UHS-II RES Packet image to this register except the response of an abort command, which is specified by setting 1h or 2h to the [7-6] CMD_TYPE bit filed. The maximum response length is 20 bytes.
  [7:0] RESP_PKT_BYTE — Response Packet Byte Host Controller saves received UHS-II RES Packet image to this register except the response of an abort command.
0xB4 MMCSD12_UHS2_MESSAGE_SELECT 8-bit access per field — This register is used to access internal buffer.
  [1:0] MSG_SEL rw — UHS-II MSG Select Host Controller holds 4 MSG packets in FIFO buffer. One of 4 MSGs can be read from the (assumed for debug usage). 0h: The latest MSG 1h: One MSG before 2h: Two MSGs before 3h: Three MSGs before
0xB8 MMCSD12_UHS2_MESSAGE 32-bit — This register is used to access internal buffer.
  [8n+7:8n] MSG_BYTE{n} (n=0..3) — UHS II MSG Host Controller holds 4 MSG packets in FIFO buffer. One of 4 MSGs (length is 4 bytes) can be read from this register by setting the
0xBC MMCSD12_UHS2_DEVICE_INTR_STATUS access not given — This register shows receipt of INT MSG from which device.
  [15:0] DEV_INT_STS — UHS-II Device Interrupt Status This register shows receipt of INT MSG from which device and is effective when the Writing a bit to 1h clears the status bit (interrupt is treated) and writing a bit to 0h keeps the status value (interrupt is untreated). If the Effective bit range of this register is determined by the D00 - Not used (Reserved) D01 - Setting 1h means INT MSG is received from Device ID 1 D02 - Setting 1h means INT MSG is received from Device ID 2 .... ..... D15 - Setting 1h means INT MSG is received from Device ID 15 (access RW1C)
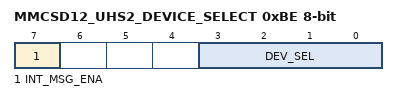
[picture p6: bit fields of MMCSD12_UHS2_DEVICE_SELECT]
0xBE MMCSD12_UHS2_DEVICE_SELECT 8-bit access per field — UHS-II Device Select Register.
  [7] INT_MSG_ENA rw — INT MSG Enable (Optional) This bit enables receipt of INT MSG. If this bit is set to 1h, receipt of INT MSG is informed by the Support of INT MSG Interrupt is optional. If trying to set this bit to 1h but still this bit is read 0, INT MSG Interrupt is not supported by the Host Controller. In this case, the 0h: Disabled 1h: Enabled
  [3:0] DEV_SEL rw — UHS-II Device Select Host Controller holds an INT MSG packet per device. One of INT MSGs (up to 15) can be selected by this field and read from the The number of devices implemented in the Host Controller is indicated by the 0h: Unselected (Default) 1h: INT MSG of Device ID 1 is selected 2h: INT MSG of Device ID 2 is selected ..... ..... Fh: INT MSG of Device ID 15 is selected
0xBF MMCSD12_UHS2_DEVICE_INT_CODE 8-bit — This register is effective when the [7] INT_MSG_ENA bit is set to 1h.
  [7:0] DEV_INTR — UHS II Device Interrupt This register is effective when the The number of the registers to hold INT MSGs is determined by the
